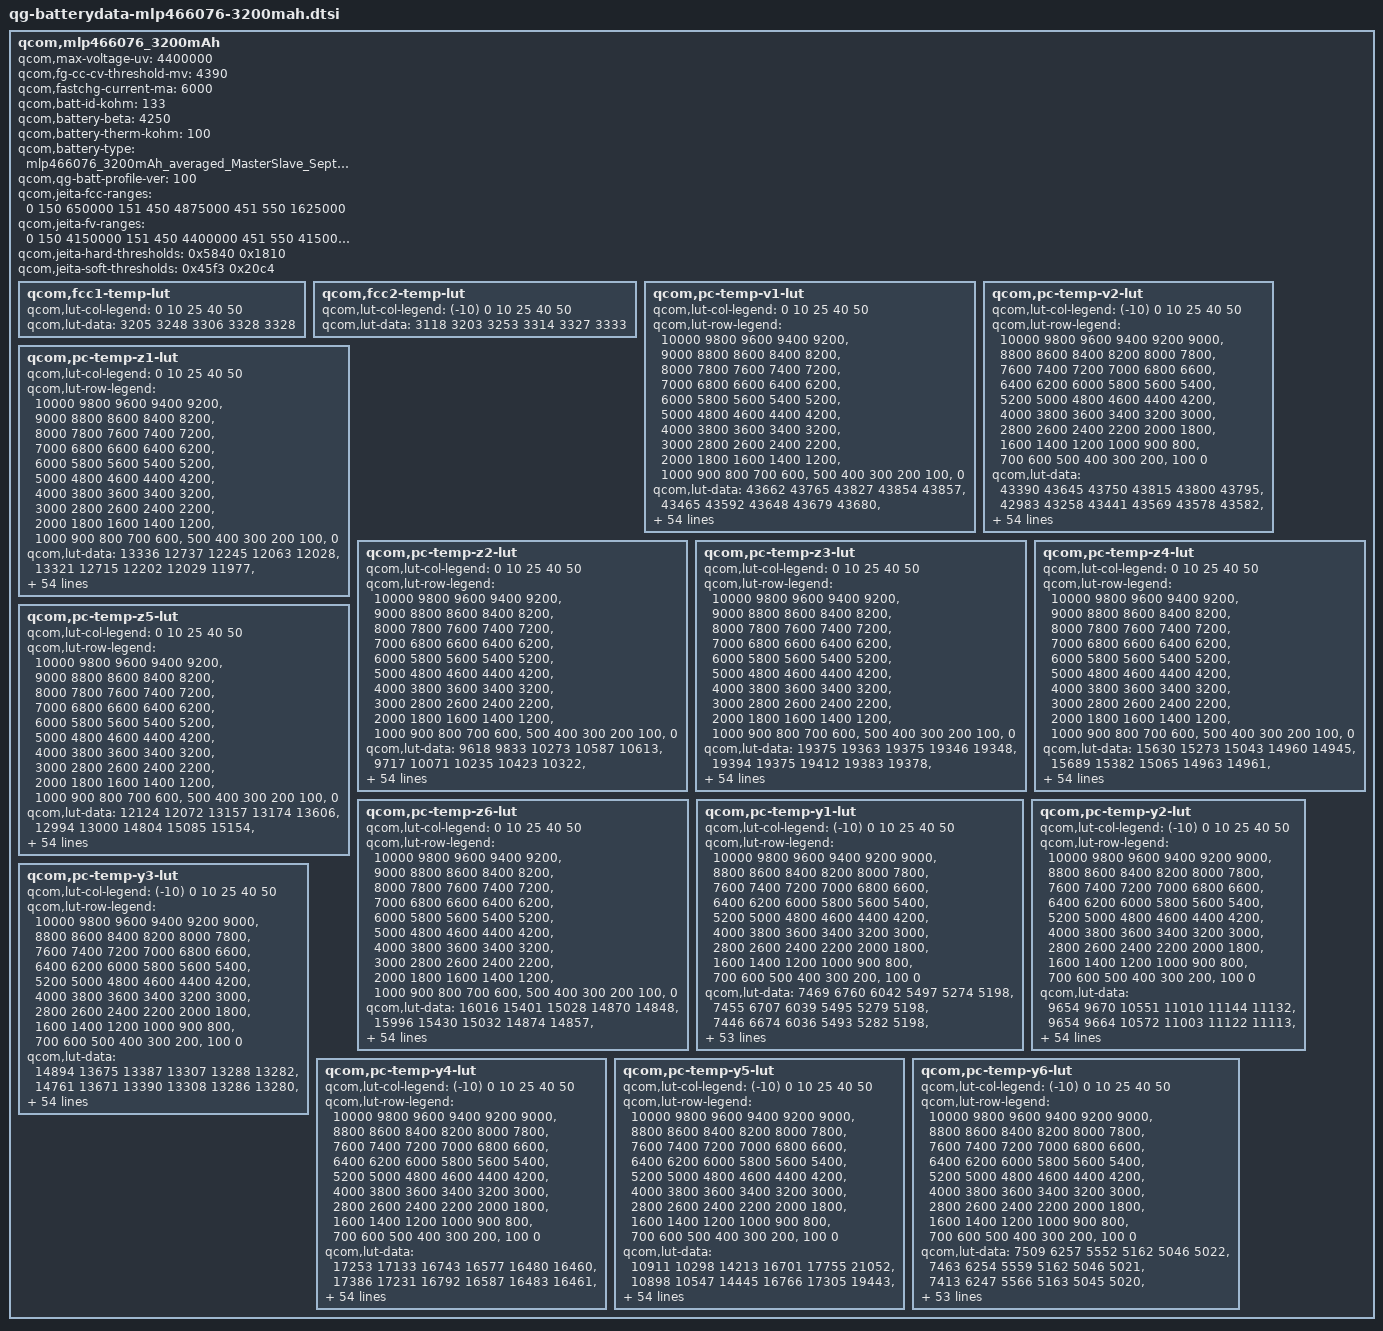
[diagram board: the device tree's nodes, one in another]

/* Copyright (c) 2018, The Linux Foundation. All rights reserved.
 *
 * This program is free software; you can redistribute it and/or modify
 * it under the terms of the GNU General Public License version 2 and
 * only version 2 as published by the Free Software Foundation.
 *
 * This program is distributed in the hope that it will be useful,
 * but WITHOUT ANY WARRANTY; without even the implied warranty of
 * MERCHANTABILITY or FITNESS FOR A PARTICULAR PURPOSE.  See the
 * GNU General Public License for more details.
 */

qcom,mlp466076_3200mAh {
	/* mlp466076_3200mAh_averaged_MasterSlave_Sept28th2018 */
	qcom,max-voltage-uv = <4400000>;
	qcom,fg-cc-cv-threshold-mv = <4390>;
	qcom,fastchg-current-ma = <6000>;
	qcom,batt-id-kohm = <133>;
	qcom,battery-beta = <4250>;
	qcom,battery-therm-kohm = <100>;
	qcom,battery-type =
		"mlp466076_3200mAh_averaged_MasterSlave_Sept28th2018";
	qcom,qg-batt-profile-ver = <100>;

	qcom,jeita-fcc-ranges = <0 150 650000
				151 450 4875000
				451 550 1625000>;
	qcom,jeita-fv-ranges = <0 150 4150000
				151 450 4400000
				451 550 4150000>;
	/* COLD = 0 DegC, HOT = 55 DegC */
	qcom,jeita-hard-thresholds = <0x5840 0x1810>;
	/* COOL = 15 DegC, WARM = 45 DegC */
	qcom,jeita-soft-thresholds = <0x45f3 0x20c4>;

	qcom,fcc1-temp-lut {
		qcom,lut-col-legend = <0 10 25 40 50>;
		qcom,lut-data = <3205 3248 3306 3328 3328>;
	};

	qcom,fcc2-temp-lut {
		qcom,lut-col-legend = <(-10) 0 10 25 40 50>;
		qcom,lut-data = <3118 3203 3253 3314 3327 3333>;
	};

	qcom,pc-temp-v1-lut {
		qcom,lut-col-legend = <0 10 25 40 50>;
		qcom,lut-row-legend = <10000 9800 9600 9400 9200>,
			<9000 8800 8600 8400 8200>,
			<8000 7800 7600 7400 7200>,
			<7000 6800 6600 6400 6200>,
			<6000 5800 5600 5400 5200>,
			<5000 4800 4600 4400 4200>,
			<4000 3800 3600 3400 3200>,
			<3000 2800 2600 2400 2200>,
			<2000 1800 1600 1400 1200>,
			<1000 900 800 700 600>,
			<500 400 300 200 100>,
			<0>;
		qcom,lut-data = <43662 43765 43827 43854 43857>,
			<43465 43592 43648 43679 43680>,
			<43244 43371 43441 43477 43474>,
			<43004 43143 43219 43263 43254>,
			<42786 42919 42991 43039 43024>,
			<42603 42692 42762 42806 42790>,
			<42425 42464 42530 42568 42557>,
			<42215 42239 42301 42330 42326>,
			<41980 42016 42073 42096 42101>,
			<41759 41797 41849 41866 41875>,
			<41557 41584 41627 41642 41650>,
			<41362 41378 41411 41424 41428>,
			<41163 41178 41202 41209 41210>,
			<40961 40977 41001 40999 40999>,
			<40760 40772 40799 40794 40793>,
			<40563 40570 40594 40597 40597>,
			<40358 40372 40396 40405 40407>,
			<40145 40178 40221 40225 40226>,
			<39945 40002 40053 40053 40050>,
			<39789 39854 39847 39858 39853>,
			<39654 39711 39576 39612 39620>,
			<39531 39519 39339 39375 39391>,
			<39412 39263 39176 39190 39200>,
			<39282 39052 39040 39032 39031>,
			<39133 38917 38919 38892 38884>,
			<38984 38816 38812 38767 38758>,
			<38858 38736 38712 38655 38645>,
			<38756 38672 38614 38553 38541>,
			<38668 38609 38524 38459 38444>,
			<38595 38544 38445 38374 38354>,
			<38533 38483 38374 38297 38270>,
			<38475 38429 38310 38226 38195>,
			<38430 38379 38253 38166 38130>,
			<38401 38330 38199 38107 38067>,
			<38377 38287 38153 38049 38003>,
			<38346 38242 38109 37990 37936>,
			<38285 38194 38057 37927 37867>,
			<38212 38141 37997 37860 37794>,
			<38144 38070 37923 37783 37713>,
			<38069 37964 37822 37685 37612>,
			<37974 37836 37698 37571 37495>,
			<37837 37691 37560 37439 37359>,
			<37673 37537 37406 37289 37206>,
			<37502 37409 37248 37138 37064>,
			<37345 37284 37128 37023 36958>,
			<37238 37184 37066 36969 36904>,
			<37204 37151 37050 36949 36887>,
			<37171 37121 37032 36932 36873>,
			<37134 37087 36999 36898 36835>,
			<37025 36967 36850 36728 36642>,
			<36701 36632 36509 36379 36285>,
			<36239 36167 36048 35916 35824>,
			<35649 35576 35460 35327 35236>,
			<34852 34778 34666 34533 34443>,
			<33622 33561 33462 33330 33238>,
			<30000 30000 30000 30000 30000>;
	};

	qcom,pc-temp-v2-lut {
		qcom,lut-col-legend = <(-10) 0 10 25 40 50>;
		qcom,lut-row-legend = <10000 9800 9600 9400 9200 9000>,
			<8800 8600 8400 8200 8000 7800>,
			<7600 7400 7200 7000 6800 6600>,
			<6400 6200 6000 5800 5600 5400>,
			<5200 5000 4800 4600 4400 4200>,
			<4000 3800 3600 3400 3200 3000>,
			<2800 2600 2400 2200 2000 1800>,
			<1600 1400 1200 1000 900 800>,
			<700 600 500 400 300 200>,
			<100 0>;
		qcom,lut-data = <43390 43645 43750 43815 43800 43795>,
			<42983 43258 43441 43569 43578 43582>,
			<42608 42904 43149 43327 43354 43366>,
			<42270 42588 42877 43089 43129 43145>,
			<41961 42304 42623 42856 42904 42921>,
			<41683 42042 42377 42623 42676 42694>,
			<41438 41791 42134 42391 42446 42463>,
			<41238 41546 41897 42160 42215 42232>,
			<41062 41317 41666 41934 41987 42003>,
			<40846 41113 41438 41710 41760 41775>,
			<40569 40968 41219 41489 41537 41550>,
			<40319 40809 41018 41270 41319 41329>,
			<40103 40562 40827 41057 41104 41111>,
			<39844 40259 40633 40856 40895 40900>,
			<39546 39953 40421 40658 40689 40693>,
			<39304 39745 40200 40455 40490 40494>,
			<39117 39574 39983 40245 40297 40302>,
			<38956 39378 39768 40043 40107 40114>,
			<38793 39156 39546 39861 39925 39933>,
			<38644 38938 39315 39676 39735 39743>,
			<38519 38742 39102 39446 39499 39505>,
			<38411 38566 38911 39183 39234 39243>,
			<38324 38421 38746 38973 39029 39041>,
			<38257 38302 38600 38817 38875 38887>,
			<38199 38211 38469 38683 38741 38752>,
			<38146 38145 38351 38560 38617 38628>,
			<38098 38091 38245 38450 38505 38515>,
			<38052 38045 38150 38347 38400 38409>,
			<38006 38004 38065 38253 38304 38311>,
			<37961 37964 37993 38163 38214 38219>,
			<37916 37925 37937 38080 38133 38135>,
			<37869 37885 37889 38001 38057 38057>,
			<37819 37842 37844 37926 37987 37985>,
			<37765 37793 37800 37855 37919 37914>,
			<37706 37743 37753 37784 37834 37819>,
			<37641 37692 37702 37716 37722 37690>,
			<37572 37633 37642 37647 37608 37564>,
			<37495 37562 37573 37569 37511 37461>,
			<37414 37476 37492 37486 37421 37368>,
			<37330 37382 37399 37399 37334 37278>,
			<37241 37277 37290 37309 37247 37186>,
			<37150 37164 37167 37199 37139 37073>,
			<37061 37043 37037 37065 37012 36948>,
			<36974 36929 36917 36918 36864 36803>,
			<36874 36836 36835 36850 36812 36762>,
			<36760 36750 36766 36819 36788 36738>,
			<36690 36703 36735 36797 36767 36721>,
			<36594 36645 36672 36765 36742 36693>,
			<36441 36551 36563 36683 36669 36598>,
			<36215 36353 36313 36466 36433 36312>,
			<35901 36016 35927 36050 36018 35886>,
			<35430 35532 35419 35522 35495 35356>,
			<34781 34891 34751 34850 34822 34674>,
			<33883 34005 33839 33929 33926 33799>,
			<32534 32590 32567 32727 32712 32584>,
			<30011 30004 30001 30000 30000 29999>;
	};

	qcom,pc-temp-z1-lut {
		qcom,lut-col-legend = <0 10 25 40 50>;
		qcom,lut-row-legend = <10000 9800 9600 9400 9200>,
			<9000 8800 8600 8400 8200>,
			<8000 7800 7600 7400 7200>,
			<7000 6800 6600 6400 6200>,
			<6000 5800 5600 5400 5200>,
			<5000 4800 4600 4400 4200>,
			<4000 3800 3600 3400 3200>,
			<3000 2800 2600 2400 2200>,
			<2000 1800 1600 1400 1200>,
			<1000 900 800 700 600>,
			<500 400 300 200 100>,
			<0>;
		qcom,lut-data = <13336 12737 12245 12063 12028>,
			<13321 12715 12202 12029 11977>,
			<13325 12709 12216 11985 11908>,
			<13384 12694 12186 11976 11728>,
			<13496 12676 12160 11969 11639>,
			<13923 12659 12154 11893 11631>,
			<14348 12649 12151 11776 11626>,
			<14398 12645 12146 11753 11623>,
			<14405 12639 12138 11752 11620>,
			<14400 12606 12131 11751 11617>,
			<14362 12571 12127 11749 11615>,
			<14304 12567 12126 11745 11614>,
			<14258 12571 12126 11742 11613>,
			<14214 12572 12126 11740 11610>,
			<14183 12588 12124 11738 11609>,
			<14141 12697 12117 11737 11609>,
			<14075 12810 12113 11737 11609>,
			<14011 12906 12116 11737 11610>,
			<13963 12974 12123 11738 11610>,
			<13946 12991 12124 11740 11610>,
			<13939 12997 12122 11742 11610>,
			<13933 12991 12120 11744 11612>,
			<13934 12994 12127 11747 11614>,
			<13946 13005 12137 11750 11617>,
			<13955 13003 12140 11754 11620>,
			<13948 12997 12140 11759 11622>,
			<13954 12995 12141 11762 11626>,
			<13959 12996 12143 11764 11629>,
			<13950 12997 12146 11765 11633>,
			<13956 13000 12149 11768 11637>,
			<13993 13006 12155 11775 11641>,
			<14015 13018 12157 11780 11645>,
			<14022 13035 12158 11783 11649>,
			<14016 13041 12160 11786 11653>,
			<14003 13041 12168 11789 11656>,
			<13991 13044 12179 11793 11660>,
			<13999 13058 12183 11799 11664>,
			<14034 13080 12184 11809 11669>,
			<14066 13093 12185 11817 11674>,
			<14095 13109 12200 11820 11679>,
			<14119 13123 12216 11822 11684>,
			<14122 13124 12214 11823 11687>,
			<14096 13124 12204 11830 11690>,
			<14077 13123 12206 11831 11693>,
			<14091 13131 12216 11832 11695>,
			<14132 13134 12220 11839 11701>,
			<14111 13151 12226 11842 11703>,
			<14099 13131 12231 11845 11707>,
			<14137 13170 12238 11848 11710>,
			<14113 13167 12233 11864 11717>,
			<14164 13173 12257 11862 11720>,
			<14159 13211 12252 11883 11727>,
			<14137 13247 12286 11882 11736>,
			<14149 13284 12290 11888 11745>,
			<14149 13284 12290 11888 11745>,
			<14149 13284 12290 11888 11745>;
	};

	qcom,pc-temp-z2-lut {
		qcom,lut-col-legend = <0 10 25 40 50>;
		qcom,lut-row-legend = <10000 9800 9600 9400 9200>,
			<9000 8800 8600 8400 8200>,
			<8000 7800 7600 7400 7200>,
			<7000 6800 6600 6400 6200>,
			<6000 5800 5600 5400 5200>,
			<5000 4800 4600 4400 4200>,
			<4000 3800 3600 3400 3200>,
			<3000 2800 2600 2400 2200>,
			<2000 1800 1600 1400 1200>,
			<1000 900 800 700 600>,
			<500 400 300 200 100>,
			<0>;
		qcom,lut-data = <9618 9833 10273 10587 10613>,
			<9717 10071 10235 10423 10322>,
			<9767 10199 10360 10416 10359>,
			<10027 10256 10382 10432 10417>,
			<10146 10256 10391 10426 10403>,
			<9854 10234 10380 10416 10359>,
			<9540 10218 10359 10403 10313>,
			<9614 10214 10345 10400 10300>,
			<9875 10209 10334 10415 10313>,
			<9964 10204 10329 10423 10330>,
			<9958 10204 10339 10396 10336>,
			<9950 10208 10353 10348 10338>,
			<9946 10211 10359 10338 10339>,
			<9943 10216 10362 10358 10338>,
			<9910 10210 10368 10373 10337>,
			<9742 10146 10380 10369 10343>,
			<9638 10109 10390 10356 10357>,
			<9760 10123 10389 10353 10377>,
			<9935 10139 10383 10357 10397>,
			<9965 10142 10386 10365 10410>,
			<9980 10142 10400 10404 10416>,
			<10008 10144 10410 10463 10423>,
			<9880 10150 10391 10527 10467>,
			<9720 10157 10363 10588 10536>,
			<9779 10171 10371 10588 10530>,
			<9972 10186 10419 10538 10402>,
			<10034 10188 10442 10493 10311>,
			<10027 10183 10423 10474 10309>,
			<10024 10181 10403 10462 10323>,
			<10022 10188 10403 10460 10329>,
			<10021 10197 10406 10460 10328>,
			<10020 10201 10411 10461 10334>,
			<10019 10205 10425 10482 10364>,
			<9912 10208 10438 10519 10399>,
			<9718 10212 10445 10557 10436>,
			<9686 10216 10450 10599 10488>,
			<9872 10220 10457 10630 10512>,
			<10038 10226 10465 10653 10510>,
			<9970 10229 10473 10670 10510>,
			<9661 10232 10488 10685 10521>,
			<9424 10234 10501 10695 10542>,
			<9380 10229 10497 10686 10581>,
			<9360 10221 10485 10657 10635>,
			<9344 10401 10482 10661 10609>,
			<9319 11186 10491 10661 10585>,
			<9305 13142 10504 10625 10613>,
			<9304 13559 10476 10620 10613>,
			<9293 12008 10464 10612 10648>,
			<9279 11863 10466 10654 10747>,
			<9266 12115 10555 10704 10597>,
			<9244 11992 10590 10647 10489>,
			<9219 10653 10578 10583 10440>,
			<9180 10297 10596 10530 10382>,
			<9154 9949 10524 10471 10317>,
			<9154 9949 10524 10471 10317>,
			<9154 9949 10524 10471 10317>;
	};

	qcom,pc-temp-z3-lut {
		qcom,lut-col-legend = <0 10 25 40 50>;
		qcom,lut-row-legend = <10000 9800 9600 9400 9200>,
			<9000 8800 8600 8400 8200>,
			<8000 7800 7600 7400 7200>,
			<7000 6800 6600 6400 6200>,
			<6000 5800 5600 5400 5200>,
			<5000 4800 4600 4400 4200>,
			<4000 3800 3600 3400 3200>,
			<3000 2800 2600 2400 2200>,
			<2000 1800 1600 1400 1200>,
			<1000 900 800 700 600>,
			<500 400 300 200 100>,
			<0>;
		qcom,lut-data = <19375 19363 19375 19346 19348>,
			<19394 19375 19412 19383 19378>,
			<19468 19500 19455 19415 19392>,
			<19623 19565 19476 19435 19361>,
			<19700 19580 19486 19440 19348>,
			<19658 19588 19489 19420 19361>,
			<19609 19591 19491 19387 19372>,
			<19662 19591 19490 19383 19370>,
			<19814 19591 19488 19389 19364>,
			<19862 19588 19485 19390 19359>,
			<19847 19579 19478 19384 19358>,
			<19826 19569 19471 19377 19357>,
			<19811 19561 19468 19374 19357>,
			<19800 19556 19465 19374 19356>,
			<19764 19563 19463 19374 19354>,
			<19601 19599 19463 19372 19350>,
			<19493 19623 19463 19370 19346>,
			<19603 19630 19460 19369 19343>,
			<19740 19634 19456 19368 19342>,
			<19729 19629 19457 19367 19342>,
			<19717 19622 19467 19370 19344>,
			<19700 19624 19473 19373 19349>,
			<19575 19644 19462 19377 19360>,
			<19507 19655 19447 19383 19375>,
			<19642 19654 19449 19389 19380>,
			<19829 19652 19464 19402 19380>,
			<19889 19647 19475 19411 19380>,
			<19884 19641 19480 19408 19376>,
			<19880 19639 19483 19403 19371>,
			<19873 19638 19481 19398 19368>,
			<19863 19638 19475 19393 19365>,
			<19854 19636 19471 19388 19362>,
			<19843 19634 19468 19385 19358>,
			<19752 19632 19465 19381 19355>,
			<19596 19631 19462 19379 19352>,
			<19561 19629 19459 19378 19349>,
			<19674 19626 19457 19377 19348>,
			<19773 19619 19455 19377 19347>,
			<19709 19612 19453 19377 19346>,
			<19460 19605 19449 19376 19347>,
			<19282 19598 19443 19373 19349>,
			<19273 19594 19440 19370 19351>,
			<19274 19589 19438 19367 19354>,
			<19274 19383 19434 19366 19352>,
			<19275 19258 19424 19363 19345>,
			<19276 19257 19403 19344 19332>,
			<19276 19257 19383 19344 19331>,
			<19277 19258 19361 19345 19324>,
			<19278 19258 19366 19342 19319>,
			<19279 19258 19361 19347 19341>,
			<19281 19258 19350 19351 19347>,
			<19284 19259 19346 19357 19349>,
			<19291 19260 19336 19360 19351>,
			<19296 19262 19330 19362 19356>,
			<19296 19262 19330 19362 19356>,
			<19296 19262 19330 19362 19356>;
	};

	qcom,pc-temp-z4-lut {
		qcom,lut-col-legend = <0 10 25 40 50>;
		qcom,lut-row-legend = <10000 9800 9600 9400 9200>,
			<9000 8800 8600 8400 8200>,
			<8000 7800 7600 7400 7200>,
			<7000 6800 6600 6400 6200>,
			<6000 5800 5600 5400 5200>,
			<5000 4800 4600 4400 4200>,
			<4000 3800 3600 3400 3200>,
			<3000 2800 2600 2400 2200>,
			<2000 1800 1600 1400 1200>,
			<1000 900 800 700 600>,
			<500 400 300 200 100>,
			<0>;
		qcom,lut-data = <15630 15273 15043 14960 14945>,
			<15689 15382 15065 14963 14961>,
			<15723 15346 15157 15020 14973>,
			<15654 15257 15080 15001 14877>,
			<15621 15154 14988 14931 14792>,
			<15743 15055 14927 14858 14759>,
			<15853 14981 14873 14788 14737>,
			<15756 14922 14829 14752 14722>,
			<15538 14876 14792 14733 14715>,
			<15404 14844 14769 14721 14709>,
			<15340 14819 14759 14716 14702>,
			<15293 14799 14752 14713 14694>,
			<15250 14783 14746 14708 14686>,
			<15214 14773 14740 14701 14680>,
			<15227 14774 14739 14695 14676>,
			<15369 14801 14741 14692 14673>,
			<15468 14820 14744 14690 14671>,
			<15361 14830 14738 14688 14670>,
			<15201 14832 14727 14685 14667>,
			<15170 14815 14736 14690 14675>,
			<15151 14789 14815 14750 14721>,
			<15127 14804 14877 14806 14764>,
			<15219 14885 14892 14809 14763>,
			<15278 14938 14900 14802 14751>,
			<15140 14940 14888 14791 14740>,
			<14941 14935 14845 14762 14727>,
			<14880 14921 14812 14737 14714>,
			<14888 14894 14794 14726 14706>,
			<14891 14871 14782 14720 14700>,
			<14891 14857 14780 14716 14695>,
			<14888 14844 14779 14715 14691>,
			<14884 14834 14779 14714 14689>,
			<14879 14825 14781 14714 14688>,
			<14953 14818 14783 14714 14687>,
			<15095 14813 14783 14718 14692>,
			<15118 14807 14782 14727 14704>,
			<14978 14801 14782 14731 14709>,
			<14853 14795 14780 14732 14711>,
			<14902 14789 14778 14733 14711>,
			<15140 14785 14771 14729 14708>,
			<15315 14780 14761 14722 14703>,
			<15314 14769 14752 14717 14701>,
			<15291 14758 14742 14712 14699>,
			<15259 14934 14730 14706 14695>,
			<15156 15013 14704 14693 14685>,
			<15078 14949 14666 14661 14654>,
			<15075 14945 14675 14647 14643>,
			<15071 14942 14689 14634 14634>,
			<15063 14935 14681 14635 14635>,
			<15049 14927 14694 14647 14637>,
			<15057 14938 14712 14649 14640>,
			<15071 14942 14718 14646 14641>,
			<15084 14949 14731 14644 14640>,
			<15105 14958 14742 14645 14638>,
			<15105 14958 14742 14645 14638>,
			<15105 14958 14742 14645 14638>;
	};

	qcom,pc-temp-z5-lut {
		qcom,lut-col-legend = <0 10 25 40 50>;
		qcom,lut-row-legend = <10000 9800 9600 9400 9200>,
			<9000 8800 8600 8400 8200>,
			<8000 7800 7600 7400 7200>,
			<7000 6800 6600 6400 6200>,
			<6000 5800 5600 5400 5200>,
			<5000 4800 4600 4400 4200>,
			<4000 3800 3600 3400 3200>,
			<3000 2800 2600 2400 2200>,
			<2000 1800 1600 1400 1200>,
			<1000 900 800 700 600>,
			<500 400 300 200 100>,
			<0>;
		qcom,lut-data = <12124 12072 13157 13174 13606>,
			<12994 13000 14804 15085 15154>,
			<13587 14583 15791 16396 16870>,
			<13874 15964 16772 16919 15801>,
			<13884 16939 17839 17371 16041>,
			<13288 17849 18811 17290 17992>,
			<12752 18889 19806 17211 20051>,
			<13155 20252 21035 17957 20337>,
			<14211 21670 22602 19862 19980>,
			<14723 22477 23646 20935 19733>,
			<14736 22953 24200 20677 20042>,
			<14649 23096 24568 19994 20872>,
			<14721 23386 24733 19863 21792>,
			<14828 23940 25087 20680 22627>,
			<14648 25256 25600 21530 22979>,
			<13383 26083 27040 21835 22568>,
			<12564 25447 28188 22062 21924>,
			<14450 24954 27982 22511 21937>,
			<16825 25408 27494 23231 22542>,
			<16732 25757 28143 23429 22575>,
			<16303 26250 33310 22605 21080>,
			<15711 28817 36779 21685 19879>,
			<13993 36697 31028 20502 19380>,
			<16429 41291 22626 18349 18894>,
			<23300 39174 21659 17982 18992>,
			<29454 35310 22858 20629 20165>,
			<31867 32664 24466 23458 21295>,
			<32326 30650 27410 25252 22111>,
			<32352 30008 30586 26767 23020>,
			<31698 30713 32388 28065 24313>,
			<30597 31769 33715 29167 26079>,
			<29641 32615 34902 30229 27629>,
			<28570 33593 36165 31554 29266>,
			<25166 34668 36865 32469 30251>,
			<20184 36022 36864 32454 29500>,
			<18967 36995 36786 32263 28117>,
			<21737 37027 36538 32001 27361>,
			<24117 36857 35657 31514 25956>,
			<22175 36546 34649 30833 24906>,
			<15699 35485 33710 29804 25141>,
			<11242 34238 32735 28436 25578>,
			<10985 33611 31645 26834 26096>,
			<10984 32850 30651 25139 26981>,
			<10998 19087 30705 25214 25567>,
			<11145 11243 30585 25077 23501>,
			<11257 11255 29211 23396 23355>,
			<11216 11222 22088 26638 26212>,
			<11217 11211 16895 30416 25864>,
			<11223 11229 17933 28658 22675>,
			<11260 11323 17117 24401 28538>,
			<11268 11309 15536 23343 28235>,
			<11186 11276 14888 24817 26689>,
			<11117 11246 13952 24826 26557>,
			<11073 11186 13396 24230 27076>,
			<11073 11186 13396 24230 27076>,
			<11073 11186 13396 24230 27076>;
	};

	qcom,pc-temp-z6-lut {
		qcom,lut-col-legend = <0 10 25 40 50>;
		qcom,lut-row-legend = <10000 9800 9600 9400 9200>,
			<9000 8800 8600 8400 8200>,
			<8000 7800 7600 7400 7200>,
			<7000 6800 6600 6400 6200>,
			<6000 5800 5600 5400 5200>,
			<5000 4800 4600 4400 4200>,
			<4000 3800 3600 3400 3200>,
			<3000 2800 2600 2400 2200>,
			<2000 1800 1600 1400 1200>,
			<1000 900 800 700 600>,
			<500 400 300 200 100>,
			<0>;
		qcom,lut-data = <16016 15401 15028 14870 14848>,
			<15996 15430 15032 14874 14857>,
			<16013 15428 15075 14902 14845>,
			<16033 15402 15037 14897 14721>,
			<16086 15344 14991 14863 14651>,
			<16361 15274 14956 14789 14644>,
			<16617 15223 14923 14701 14637>,
			<16582 15181 14896 14678 14629>,
			<16509 15146 14871 14671 14622>,
			<16437 15116 14854 14665 14616>,
			<16363 15091 14843 14658 14611>,
			<16293 15068 14836 14652 14607>,
			<16231 15048 14830 14648 14603>,
			<16173 15033 14826 14645 14600>,
			<16114 15039 14823 14642 14596>,
			<16055 15104 14821 14639 14593>,
			<16013 15166 14819 14636 14590>,
			<15987 15206 14815 14635 14588>,
			<15960 15231 14810 14633 14587>,
			<15927 15226 14815 14636 14590>,
			<15890 15215 14856 14663 14611>,
			<15856 15224 14886 14690 14632>,
			<15831 15272 14888 14694 14639>,
			<15823 15302 14886 14695 14642>,
			<15833 15304 14882 14695 14642>,
			<15847 15302 14874 14690 14637>,
			<15856 15296 14868 14684 14631>,
			<15863 15284 14864 14679 14625>,
			<15866 15276 14862 14675 14621>,
			<15866 15272 14861 14671 14617>,
			<15865 15269 14859 14668 14615>,
			<15862 15267 14859 14666 14613>,
			<15859 15265 14860 14665 14610>,
			<15852 15265 14861 14664 14609>,
			<15844 15268 14863 14666 14610>,
			<15842 15271 14865 14670 14614>,
			<15848 15272 14866 14673 14617>,
			<15853 15272 14868 14675 14618>,
			<15851 15272 14869 14676 14618>,
			<15844 15275 14867 14675 14618>,
			<15839 15279 14864 14672 14617>,
			<15842 15282 14863 14669 14618>,
			<15846 15284 14862 14667 14620>,
			<15845 15274 14860 14666 14618>,
			<15825 15253 14851 14661 14611>,
			<15802 15242 14830 14638 14592>,
			<15802 15243 14825 14633 14586>,
			<15804 15246 14823 14629 14579>,
			<15809 15251 14826 14629 14578>,
			<15817 15257 14834 14638 14591>,
			<15831 15272 14842 14644 14598>,
			<15851 15287 14848 14648 14600>,
			<15875 15306 14857 14652 14603>,
			<15910 15332 14869 14657 14608>,
			<15910 15332 14869 14657 14608>,
			<15910 15332 14869 14657 14608>;
	};

	qcom,pc-temp-y1-lut {
		qcom,lut-col-legend = <(-10) 0 10 25 40 50>;
		qcom,lut-row-legend = <10000 9800 9600 9400 9200 9000>,
			<8800 8600 8400 8200 8000 7800>,
			<7600 7400 7200 7000 6800 6600>,
			<6400 6200 6000 5800 5600 5400>,
			<5200 5000 4800 4600 4400 4200>,
			<4000 3800 3600 3400 3200 3000>,
			<2800 2600 2400 2200 2000 1800>,
			<1600 1400 1200 1000 900 800>,
			<700 600 500 400 300 200>,
			<100 0>;
		qcom,lut-data = <7469 6760 6042 5497 5274 5198>,
			<7455 6707 6039 5495 5279 5198>,
			<7446 6674 6036 5493 5282 5198>,
			<7441 6657 6033 5492 5283 5196>,
			<7439 6651 6030 5492 5282 5194>,
			<7438 6650 6029 5492 5281 5191>,
			<7435 6671 6029 5490 5278 5188>,
			<7457 6694 6031 5488 5274 5184>,
			<7493 6691 6032 5488 5271 5182>,
			<7523 6673 6036 5489 5269 5179>,
			<7534 6667 6039 5489 5266 5178>,
			<7533 6670 6042 5486 5262 5176>,
			<7509 6674 6043 5484 5260 5175>,
			<7462 6673 6041 5488 5259 5174>,
			<7430 6668 6043 5496 5258 5173>,
			<7429 6670 6047 5497 5257 5173>,
			<7440 6686 6046 5494 5255 5172>,
			<7451 6697 6045 5491 5254 5172>,
			<7461 6689 6051 5490 5254 5171>,
			<7470 6688 6064 5489 5254 5171>,
			<7467 6709 6073 5490 5254 5172>,
			<7453 6738 6074 5493 5256 5173>,
			<7447 6737 6069 5494 5257 5174>,
			<7466 6706 6057 5493 5258 5174>,
			<7488 6684 6045 5492 5259 5175>,
			<7488 6689 6045 5497 5260 5176>,
			<7479 6704 6053 5504 5261 5179>,
			<7481 6706 6065 5507 5263 5180>,
			<7480 6690 6067 5505 5266 5180>,
			<7474 6678 6068 5504 5269 5181>,
			<7470 6685 6071 5506 5271 5183>,
			<7475 6700 6068 5510 5272 5186>,
			<7487 6701 6058 5510 5274 5188>,
			<7506 6693 6054 5511 5278 5190>,
			<7505 6688 6053 5514 5282 5193>,
			<7479 6697 6054 5525 5287 5196>,
			<7461 6709 6058 5534 5290 5198>,
			<7474 6706 6065 5532 5290 5201>,
			<7509 6692 6071 5525 5289 5204>,
			<7535 6679 6068 5523 5290 5206>,
			<7557 6670 6052 5530 5294 5207>,
			<7562 6667 6053 5530 5299 5210>,
			<7500 6668 6060 5522 5304 5215>,
			<7457 6704 6072 5530 5307 5216>,
			<7452 6712 6072 5531 5305 5219>,
			<7456 6691 6057 5530 5309 5222>,
			<7457 6715 6070 5540 5311 5222>,
			<7463 6729 6073 5535 5310 5225>,
			<7518 6729 6079 5539 5324 5221>,
			<7582 6694 6086 5548 5318 5222>,
			<7580 6700 6062 5567 5316 5228>,
			<7670 6739 6071 5571 5325 5234>,
			<7673 6736 6087 5567 5337 5241>,
			<7747 6806 6107 5572 5339 5245>,
			<7747 6806 6107 5572 5339 5245>,
			<7747 6806 6107 5572 5339 5245>;
	};

	qcom,pc-temp-y2-lut {
		qcom,lut-col-legend = <(-10) 0 10 25 40 50>;
		qcom,lut-row-legend = <10000 9800 9600 9400 9200 9000>,
			<8800 8600 8400 8200 8000 7800>,
			<7600 7400 7200 7000 6800 6600>,
			<6400 6200 6000 5800 5600 5400>,
			<5200 5000 4800 4600 4400 4200>,
			<4000 3800 3600 3400 3200 3000>,
			<2800 2600 2400 2200 2000 1800>,
			<1600 1400 1200 1000 900 800>,
			<700 600 500 400 300 200>,
			<100 0>;
		qcom,lut-data = <9654 9670 10551 11010 11144 11132>,
			<9654 9664 10572 11003 11122 11113>,
			<9654 9666 10596 10986 11100 11091>,
			<9655 9674 10618 10965 11080 11067>,
			<9655 9685 10634 10947 11062 11042>,
			<9655 9700 10639 10938 11050 11014>,
			<9655 9826 10635 10918 11042 10979>,
			<9655 9962 10629 10897 11034 10951>,
			<9656 9921 10625 10894 11006 10941>,
			<9656 9908 10620 10889 10959 10936>,
			<9655 10020 10617 10888 10942 10937>,
			<9655 10154 10637 10888 10942 10942>,
			<9656 10128 10673 10889 10944 10946>,
			<9655 9942 10721 10887 10956 10950>,
			<9655 9749 10784 10886 10981 10953>,
			<9655 9706 10811 10900 11006 10948>,
			<9655 9705 10823 10951 11037 10930>,
			<9655 9700 10828 11000 11067 10930>,
			<9655 9692 10813 11041 11113 11023>,
			<9655 9685 10791 11070 11148 11118>,
			<9655 9680 10790 11066 11141 11127>,
			<9655 9676 10807 11047 11122 11129>,
			<9655 9674 10824 11039 11127 11139>,
			<9654 9674 10780 11055 11159 11171>,
			<9654 9673 10518 11070 11188 11189>,
			<9654 9671 10349 11080 11202 11180>,
			<9654 9669 10440 11101 11206 11175>,
			<9654 9666 10556 11106 11215 11189>,
			<9654 9665 10441 11109 11252 11206>,
			<9654 9663 10297 11110 11284 11234>,
			<9654 9661 10243 11114 11292 11309>,
			<9654 9660 10211 11117 11300 11366>,
			<9654 9659 10170 11102 11321 11364>,
			<9654 9657 10101 11060 11352 11337>,
			<9654 9656 9980 11044 11359 11314>,
			<9654 9656 9877 11079 11336 11289>,
			<9654 9655 9821 11113 11306 11280>,
			<9654 9654 9774 11098 11289 11291>,
			<9654 9654 9727 11051 11276 11300>,
			<9654 9654 9699 11010 11276 11302>,
			<9654 9654 9686 10969 11341 11310>,
			<9654 9653 9680 10925 11388 11308>,
			<9654 9653 9674 10873 11365 11311>,
			<9654 9653 9668 10788 11287 11336>,
			<9653 9653 9665 10704 11273 11333>,
			<9653 9653 9663 10732 11295 11236>,
			<9653 9653 9662 10795 11303 11164>,
			<9653 9653 9661 10797 11232 11154>,
			<9653 9653 9660 10768 11213 11165>,
			<9652 9653 9659 10741 11214 11105>,
			<9651 9653 9658 10661 11159 11059>,
			<9650 9652 9657 10616 11088 11003>,
			<9650 9651 9656 10566 10982 10904>,
			<9648 9650 9655 10519 10871 10771>,
			<9648 9650 9655 10519 10871 10771>,
			<9648 9650 9655 10519 10871 10771>;
	};

	qcom,pc-temp-y3-lut {
		qcom,lut-col-legend = <(-10) 0 10 25 40 50>;
		qcom,lut-row-legend = <10000 9800 9600 9400 9200 9000>,
			<8800 8600 8400 8200 8000 7800>,
			<7600 7400 7200 7000 6800 6600>,
			<6400 6200 6000 5800 5600 5400>,
			<5200 5000 4800 4600 4400 4200>,
			<4000 3800 3600 3400 3200 3000>,
			<2800 2600 2400 2200 2000 1800>,
			<1600 1400 1200 1000 900 800>,
			<700 600 500 400 300 200>,
			<100 0>;
		qcom,lut-data = <14894 13675 13387 13307 13288 13282>,
			<14761 13671 13390 13308 13286 13280>,
			<14612 13660 13393 13309 13284 13279>,
			<14466 13645 13396 13310 13283 13278>,
			<14339 13628 13399 13311 13282 13278>,
			<14251 13610 13402 13312 13282 13278>,
			<14211 13592 13404 13313 13283 13278>,
			<14196 13568 13406 13313 13284 13279>,
			<14179 13541 13408 13314 13284 13279>,
			<14129 13512 13411 13315 13283 13280>,
			<14073 13500 13412 13316 13283 13280>,
			<14057 13502 13412 13316 13285 13281>,
			<14063 13505 13412 13317 13287 13281>,
			<14032 13507 13410 13317 13288 13280>,
			<13973 13505 13404 13318 13290 13280>,
			<13957 13504 13396 13318 13290 13280>,
			<13957 13504 13389 13319 13291 13282>,
			<13959 13496 13381 13319 13291 13284>,
			<13962 13479 13372 13318 13293 13287>,
			<13967 13456 13362 13315 13295 13288>,
			<13982 13429 13355 13311 13292 13285>,
			<14014 13403 13350 13305 13285 13279>,
			<14050 13387 13346 13301 13283 13277>,
			<14095 13378 13340 13298 13282 13277>,
			<14145 13378 13330 13297 13282 13277>,
			<14193 13390 13318 13296 13281 13276>,
			<14243 13411 13306 13296 13279 13276>,
			<14295 13435 13293 13296 13279 13276>,
			<14353 13462 13273 13296 13279 13276>,
			<14413 13494 13260 13295 13280 13276>,
			<14474 13533 13260 13295 13280 13275>,
			<14537 13580 13261 13294 13281 13275>,
			<14602 13634 13261 13294 13281 13276>,
			<14670 13695 13261 13293 13282 13276>,
			<14736 13767 13264 13293 13282 13276>,
			<14799 13851 13282 13294 13280 13276>,
			<14862 13945 13312 13294 13279 13275>,
			<14926 14048 13331 13291 13279 13275>,
			<14990 14162 13335 13284 13279 13275>,
			<15053 14281 13336 13283 13278 13275>,
			<15115 14406 13343 13290 13278 13275>,
			<15180 14531 13361 13293 13278 13275>,
			<15247 14652 13395 13294 13277 13275>,
			<15325 14760 13446 13296 13277 13274>,
			<15372 14809 13489 13296 13278 13275>,
			<15544 14923 13525 13303 13280 13277>,
			<15659 14973 13563 13309 13281 13280>,
			<15786 14998 13617 13315 13286 13283>,
			<15982 14992 13666 13319 13288 13283>,
			<16341 15053 13698 13323 13286 13281>,
			<16796 15132 13761 13324 13287 13281>,
			<17451 15263 13864 13331 13289 13283>,
			<18369 15740 13993 13343 13291 13285>,
			<19582 16580 14194 13360 13296 13288>,
			<19582 16580 14194 13360 13296 13288>,
			<19582 16580 14194 13360 13296 13288>;
	};

	qcom,pc-temp-y4-lut {
		qcom,lut-col-legend = <(-10) 0 10 25 40 50>;
		qcom,lut-row-legend = <10000 9800 9600 9400 9200 9000>,
			<8800 8600 8400 8200 8000 7800>,
			<7600 7400 7200 7000 6800 6600>,
			<6400 6200 6000 5800 5600 5400>,
			<5200 5000 4800 4600 4400 4200>,
			<4000 3800 3600 3400 3200 3000>,
			<2800 2600 2400 2200 2000 1800>,
			<1600 1400 1200 1000 900 800>,
			<700 600 500 400 300 200>,
			<100 0>;
		qcom,lut-data = <17253 17133 16743 16577 16480 16460>,
			<17386 17231 16792 16587 16483 16461>,
			<17568 17323 16861 16596 16486 16461>,
			<17760 17403 16932 16602 16488 16461>,
			<17920 17464 16989 16607 16489 16461>,
			<18007 17499 17012 16608 16489 16461>,
			<18009 17502 17012 16606 16488 16461>,
			<17988 17500 17010 16602 16487 16462>,
			<17999 17543 17006 16600 16488 16463>,
			<18041 17680 16996 16599 16491 16465>,
			<17967 17812 16989 16599 16494 16467>,
			<17844 17840 17026 16601 16497 16469>,
			<17736 17724 17085 16607 16500 16472>,
			<17602 17539 17128 16618 16505 16479>,
			<17436 17339 17166 16635 16511 16487>,
			<17320 17297 17151 16652 16520 16495>,
			<17244 17301 17110 16668 16534 16503>,
			<17191 17252 17064 16689 16553 16515>,
			<17124 17151 17004 16737 16591 16542>,
			<17061 17040 16905 16780 16622 16564>,
			<17025 16955 16810 16741 16596 16545>,
			<17000 16890 16734 16612 16522 16494>,
			<16985 16845 16684 16548 16487 16471>,
			<16978 16817 16665 16531 16476 16462>,
			<16977 16803 16663 16522 16471 16460>,
			<16983 16798 16662 16519 16472 16460>,
			<16991 16794 16658 16518 16474 16461>,
			<17001 16792 16662 16518 16477 16464>,
			<17010 16794 16686 16521 16481 16468>,
			<17020 16799 16701 16525 16486 16473>,
			<17027 16808 16700 16529 16495 16481>,
			<17033 16819 16703 16532 16507 16490>,
			<17039 16831 16711 16532 16521 16502>,
			<17046 16844 16721 16528 16536 16513>,
			<17054 16856 16725 16523 16536 16511>,
			<17064 16874 16716 16507 16502 16483>,
			<17071 16892 16701 16493 16470 16463>,
			<17073 16896 16700 16494 16460 16460>,
			<17074 16895 16718 16497 16455 16458>,
			<17078 16898 16740 16501 16456 16458>,
			<17086 16907 16756 16509 16461 16460>,
			<17100 16916 16766 16520 16461 16457>,
			<17127 16927 16777 16533 16464 16458>,
			<17151 16945 16788 16535 16451 16440>,
			<17171 16968 16822 16535 16453 16444>,
			<17277 17044 16856 16576 16475 16464>,
			<17341 17101 16922 16610 16490 16483>,
			<17410 17129 16953 16651 16514 16518>,
			<17486 17107 17015 16692 16536 16519>,
			<17605 17116 17023 16691 16503 16472>,
			<17753 17101 17030 16669 16495 16475>,
			<17998 17092 17063 16706 16514 16494>,
			<18444 17292 17132 16776 16554 16536>,
			<19473 17868 17327 16903 16672 16712>,
			<19473 17868 17327 16903 16672 16712>,
			<19473 17868 17327 16903 16672 16712>;
	};

	qcom,pc-temp-y5-lut {
		qcom,lut-col-legend = <(-10) 0 10 25 40 50>;
		qcom,lut-row-legend = <10000 9800 9600 9400 9200 9000>,
			<8800 8600 8400 8200 8000 7800>,
			<7600 7400 7200 7000 6800 6600>,
			<6400 6200 6000 5800 5600 5400>,
			<5200 5000 4800 4600 4400 4200>,
			<4000 3800 3600 3400 3200 3000>,
			<2800 2600 2400 2200 2000 1800>,
			<1600 1400 1200 1000 900 800>,
			<700 600 500 400 300 200>,
			<100 0>;
		qcom,lut-data = <10911 10298 14213 16701 17755 21052>,
			<10898 10547 14445 16766 17305 19443>,
			<10949 10923 14667 16781 16536 18148>,
			<11030 11360 14873 16758 15705 17155>,
			<11105 11790 15060 16708 15066 16451>,
			<11140 12156 15225 16638 14868 16040>,
			<11427 12622 15397 16476 14926 16016>,
			<12770 12870 15521 16320 14987 16092>,
			<13889 12496 15526 16267 14730 15883>,
			<13648 12382 15474 16192 14147 15511>,
			<12823 13043 15351 16067 14037 15384>,
			<13350 13999 14703 15767 14366 15172>,
			<14369 14322 14084 15374 14619 14868>,
			<13835 13655 14198 14817 14642 14286>,
			<12387 13207 14689 14237 14597 13690>,
			<11862 13518 15158 14092 14432 13665>,
			<11843 14013 15618 14088 14125 13889>,
			<11872 14061 16032 14147 14029 14160>,
			<11697 13724 16290 14567 14307 14509>,
			<11496 13360 16491 15286 14746 14893>,
			<11296 12874 16629 16221 15422 15320>,
			<11018 12157 16685 17422 16386 15876>,
			<10915 11509 16661 17766 16912 16362>,
			<10937 11055 16364 17245 17282 17294>,
			<10949 10862 15125 16788 17482 17704>,
			<10928 10863 14139 16796 17047 17507>,
			<10893 10892 13688 16847 16257 17185>,
			<10862 10972 13103 16906 15960 16859>,
			<10846 11049 11861 16955 16035 16391>,
			<10863 11085 11085 16970 16245 16032>,
			<10920 11156 11094 16960 16494 15813>,
			<11002 11238 11065 16985 16807 15733>,
			<11078 11244 11007 17138 17386 15954>,
			<11131 11221 10960 17460 18188 16486>,
			<11133 11274 11023 17775 18436 17083>,
			<11097 11459 11423 18423 18423 17731>,
			<11069 11605 11910 18965 18423 18211>,
			<11060 11618 12071 17553 19122 18678>,
			<11055 11604 12039 14324 19839 19105>,
			<11037 11603 11978 13643 19020 19029>,
			<11002 11612 11919 15021 17826 18387>,
			<10971 11599 11823 15233 17990 17895>,
			<10972 11465 11745 14656 16514 17780>,
			<11158 11428 11876 14911 18206 19748>,
			<11212 11498 11959 14662 17928 18323>,
			<11369 11538 11852 15035 16485 16557>,
			<11571 11627 12089 15093 15314 16819>,
			<11625 11902 12653 15141 16476 16374>,
			<11579 12519 13295 14848 16431 16247>,
			<11380 12618 13272 15759 17268 17871>,
			<11028 12392 13194 15990 18549 17841>,
			<10501 11978 13207 15787 18547 18581>,
			<10084 11290 12982 15884 18113 18317>,
			<9775 10649 12845 16062 18034 18316>,
			<9775 10649 12845 16062 18034 18316>,
			<9775 10649 12845 16062 18034 18316>;
	};

	qcom,pc-temp-y6-lut {
		qcom,lut-col-legend = <(-10) 0 10 25 40 50>;
		qcom,lut-row-legend = <10000 9800 9600 9400 9200 9000>,
			<8800 8600 8400 8200 8000 7800>,
			<7600 7400 7200 7000 6800 6600>,
			<6400 6200 6000 5800 5600 5400>,
			<5200 5000 4800 4600 4400 4200>,
			<4000 3800 3600 3400 3200 3000>,
			<2800 2600 2400 2200 2000 1800>,
			<1600 1400 1200 1000 900 800>,
			<700 600 500 400 300 200>,
			<100 0>;
		qcom,lut-data = <7509 6257 5552 5162 5046 5022>,
			<7463 6254 5559 5162 5046 5021>,
			<7413 6247 5566 5163 5045 5020>,
			<7363 6237 5570 5163 5044 5019>,
			<7317 6225 5572 5162 5044 5018>,
			<7278 6214 5572 5162 5043 5018>,
			<7243 6201 5566 5160 5043 5018>,
			<7222 6185 5556 5157 5042 5019>,
			<7224 6169 5548 5155 5042 5019>,
			<7201 6173 5539 5153 5042 5020>,
			<7139 6196 5532 5152 5042 5020>,
			<7087 6209 5536 5152 5044 5021>,
			<7056 6178 5547 5152 5046 5022>,
			<6999 6115 5554 5154 5048 5024>,
			<6917 6048 5556 5158 5050 5025>,
			<6873 6034 5546 5163 5053 5028>,
			<6851 6036 5529 5167 5057 5031>,
			<6842 6018 5510 5173 5063 5036>,
			<6825 5983 5485 5185 5075 5045>,
			<6811 5944 5450 5195 5085 5053>,
			<6818 5914 5419 5182 5075 5045>,
			<6840 5894 5395 5141 5049 5026>,
			<6866 5889 5380 5120 5037 5018>,
			<6900 5891 5370 5113 5033 5015>,
			<6939 5897 5361 5110 5032 5014>,
			<6977 5914 5357 5110 5032 5014>,
			<7015 5942 5356 5110 5032 5015>,
			<7055 5972 5354 5110 5032 5015>,
			<7098 6006 5353 5112 5034 5016>,
			<7142 6046 5355 5114 5036 5018>,
			<7189 6091 5362 5117 5039 5020>,
			<7238 6142 5372 5119 5043 5023>,
			<7287 6197 5384 5120 5048 5027>,
			<7337 6258 5398 5120 5054 5031>,
			<7385 6325 5416 5120 5054 5030>,
			<7432 6399 5439 5119 5044 5022>,
			<7479 6479 5466 5117 5034 5017>,
			<7525 6560 5497 5117 5032 5016>,
			<7573 6645 5535 5117 5031 5016>,
			<7622 6734 5578 5119 5031 5016>,
			<7671 6829 5627 5130 5033 5017>,
			<7725 6923 5681 5142 5034 5016>,
			<7782 7014 5743 5151 5035 5017>,
			<7845 7098 5815 5160 5032 5012>,
			<7891 7143 5876 5164 5035 5014>,
			<8048 7251 5926 5190 5043 5022>,
			<8152 7306 5983 5210 5048 5029>,
			<8272 7333 6038 5233 5060 5042>,
			<8457 7327 6100 5254 5067 5042>,
			<8797 7374 6135 5262 5057 5027>,
			<9221 7430 6200 5263 5056 5028>,
			<9832 7529 6307 5294 5065 5036>,
			<10714 7994 6439 5339 5079 5051>,
			<11882 8845 6653 5404 5118 5105>,
			<11882 8845 6653 5404 5118 5105>,
			<11882 8845 6653 5404 5118 5105>;
	};
};
